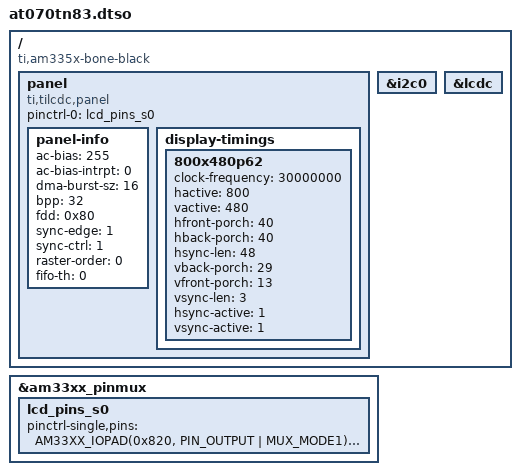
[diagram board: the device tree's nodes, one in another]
// dts overlay for at070tn83 on beaglebone black

/plugin/;
/ {
	compatible = "ti,am335x-bone-black", "ti,am335x-bone", "ti,am33xx";

	panel {
		compatible = "ti,tilcdc,panel";
		status = "okay";
		pinctrl-names = "default";
		pinctrl-0 = <&lcd_pins_s0>;
		panel-info {
			ac-bias           = <255>;
			ac-bias-intrpt    = <0>;
			dma-burst-sz      = <16>;
			bpp               = <32>;
			fdd               = <0x80>;
			sync-edge         = <1>;
			sync-ctrl         = <1>;
			raster-order      = <0>;
			fifo-th           = <0>;
		};

		display-timings {
			800x480p62 {
				clock-frequency = <30000000>;
				hactive = <800>;
				vactive = <480>;
				hfront-porch = <40>;
				hback-porch = <40>;
				hsync-len = <48>;
				vback-porch = <29>;
				vfront-porch = <13>;
				vsync-len = <3>;
				hsync-active = <1>;
				vsync-active = <1>;
			};
		};
	};

	&i2c0 {
	};
	
	&lcdc {
		status = "okay";
	}

    fragment@0 {
        target = <&am33xx_pinmux>;
        __overlay__ {
			lcd_pins_s0: lcd_pins_s0 {
				pinctrl-single,pins = <
					AM33XX_IOPAD(0x820, PIN_OUTPUT | MUX_MODE1)		/* gpmc_ad8.lcd_data23 */
					AM33XX_IOPAD(0x824, PIN_OUTPUT | MUX_MODE1)		/* gpmc_ad9.lcd_data22 */
					AM33XX_IOPAD(0x828, PIN_OUTPUT | MUX_MODE1)		/* gpmc_ad10.lcd_data21 */
					AM33XX_IOPAD(0x82c, PIN_OUTPUT | MUX_MODE1)		/* gpmc_ad11.lcd_data20 */
					AM33XX_IOPAD(0x830, PIN_OUTPUT | MUX_MODE1)		/* gpmc_ad12.lcd_data19 */
					AM33XX_IOPAD(0x834, PIN_OUTPUT | MUX_MODE1)		/* gpmc_ad13.lcd_data18 */
					AM33XX_IOPAD(0x838, PIN_OUTPUT | MUX_MODE1)		/* gpmc_ad14.lcd_data17 */
					AM33XX_IOPAD(0x83c, PIN_OUTPUT | MUX_MODE1)		/* gpmc_ad15.lcd_data16 */
					AM33XX_IOPAD(0x8a0, PIN_OUTPUT | MUX_MODE0)		/* lcd_data0.lcd_data0 */
					AM33XX_IOPAD(0x8a4, PIN_OUTPUT | MUX_MODE0)		/* lcd_data1.lcd_data1 */
					AM33XX_IOPAD(0x8a8, PIN_OUTPUT | MUX_MODE0)		/* lcd_data2.lcd_data2 */
					AM33XX_IOPAD(0x8ac, PIN_OUTPUT | MUX_MODE0)		/* lcd_data3.lcd_data3 */
					AM33XX_IOPAD(0x8b0, PIN_OUTPUT | MUX_MODE0)		/* lcd_data4.lcd_data4 */
					AM33XX_IOPAD(0x8b4, PIN_OUTPUT | MUX_MODE0)		/* lcd_data5.lcd_data5 */
					AM33XX_IOPAD(0x8b8, PIN_OUTPUT | MUX_MODE0)		/* lcd_data6.lcd_data6 */
					AM33XX_IOPAD(0x8bc, PIN_OUTPUT | MUX_MODE0)		/* lcd_data7.lcd_data7 */
					AM33XX_IOPAD(0x8c0, PIN_OUTPUT | MUX_MODE0)		/* lcd_data8.lcd_data8 */
					AM33XX_IOPAD(0x8c4, PIN_OUTPUT | MUX_MODE0)		/* lcd_data9.lcd_data9 */
					AM33XX_IOPAD(0x8c8, PIN_OUTPUT | MUX_MODE0)		/* lcd_data10.lcd_data10 */
					AM33XX_IOPAD(0x8cc, PIN_OUTPUT | MUX_MODE0)		/* lcd_data11.lcd_data11 */
					AM33XX_IOPAD(0x8d0, PIN_OUTPUT | MUX_MODE0)		/* lcd_data12.lcd_data12 */
					AM33XX_IOPAD(0x8d4, PIN_OUTPUT | MUX_MODE0)		/* lcd_data13.lcd_data13 */
					AM33XX_IOPAD(0x8d8, PIN_OUTPUT | MUX_MODE0)		/* lcd_data14.lcd_data14 */
					AM33XX_IOPAD(0x8dc, PIN_OUTPUT | MUX_MODE0)		/* lcd_data15.lcd_data15 */
					AM33XX_IOPAD(0x8e0, PIN_OUTPUT | MUX_MODE0)		/* lcd_vsync.lcd_vsync */
					AM33XX_IOPAD(0x8e4, PIN_OUTPUT | MUX_MODE0)		/* lcd_hsync.lcd_hsync */
					AM33XX_IOPAD(0x8e8, PIN_OUTPUT | MUX_MODE0)		/* lcd_pclk.lcd_pclk */
					AM33XX_IOPAD(0x8ec, PIN_OUTPUT | MUX_MODE0)		/* lcd_ac_bias_en.lcd_ac_bias_en */
				>;
			};
        };
    };
};
